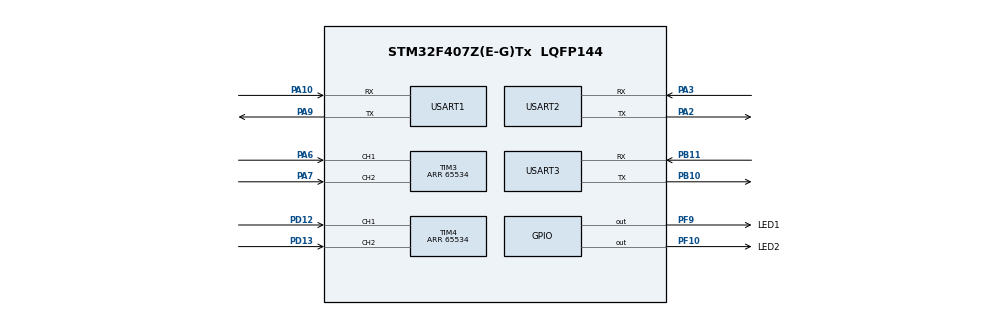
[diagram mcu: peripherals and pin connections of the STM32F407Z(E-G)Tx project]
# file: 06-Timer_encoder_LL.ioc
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Dma.Request0=USART1_TX
Dma.Request1=USART2_TX
Dma.Request2=USART3_TX
Dma.USART1_TX.0.Direction=DMA_MEMORY_TO_PERIPH
Dma.USART1_TX.0.FIFOMode=DMA_FIFOMODE_DISABLE
Dma.USART1_TX.0.Instance=DMA2_Stream7
Dma.USART1_TX.0.MemDataAlignment=DMA_MDATAALIGN_BYTE
Dma.USART1_TX.0.MemInc=DMA_MINC_ENABLE
Dma.USART1_TX.0.Mode=DMA_NORMAL
Dma.USART1_TX.0.PeriphDataAlignment=DMA_PDATAALIGN_BYTE
Dma.USART1_TX.0.PeriphInc=DMA_PINC_DISABLE
Dma.USART1_TX.0.Priority=DMA_PRIORITY_LOW
Dma.USART2_TX.1.Direction=DMA_MEMORY_TO_PERIPH
Dma.USART2_TX.1.FIFOMode=DMA_FIFOMODE_DISABLE
Dma.USART2_TX.1.Instance=DMA1_Stream6
Dma.USART2_TX.1.MemDataAlignment=DMA_MDATAALIGN_BYTE
Dma.USART2_TX.1.MemInc=DMA_MINC_ENABLE
Dma.USART2_TX.1.Mode=DMA_NORMAL
Dma.USART2_TX.1.PeriphDataAlignment=DMA_PDATAALIGN_BYTE
Dma.USART2_TX.1.PeriphInc=DMA_PINC_DISABLE
Dma.USART2_TX.1.Priority=DMA_PRIORITY_LOW
Dma.USART3_TX.2.Direction=DMA_MEMORY_TO_PERIPH
Dma.USART3_TX.2.FIFOMode=DMA_FIFOMODE_DISABLE
Dma.USART3_TX.2.Instance=DMA1_Stream3
Dma.USART3_TX.2.MemDataAlignment=DMA_MDATAALIGN_BYTE
Dma.USART3_TX.2.MemInc=DMA_MINC_ENABLE
Dma.USART3_TX.2.Mode=DMA_NORMAL
Dma.USART3_TX.2.PeriphDataAlignment=DMA_PDATAALIGN_BYTE
Dma.USART3_TX.2.PeriphInc=DMA_PINC_DISABLE
Dma.USART3_TX.2.Priority=DMA_PRIORITY_LOW
Mcu.Family=STM32F4
Mcu.Name=STM32F407Z(E-G)Tx
Mcu.Package=LQFP144
NVIC.DMA1_Stream3_IRQn=true\:0\:0\:false\:false\:true\:false\:true
NVIC.DMA1_Stream6_IRQn=true\:0\:0\:false\:false\:true\:false\:true
NVIC.DMA2_Stream7_IRQn=true\:0\:0\:false\:false\:true\:false\:true
NVIC.PriorityGroup=NVIC_PRIORITYGROUP_4
NVIC.TIM2_IRQn=true\:0\:0\:false\:false\:true\:true\:true
PA10.Mode=Asynchronous
PA10.Signal=USART1_RX
PA13.Mode=Serial_Wire
PA13.Signal=SYS_JTMS-SWDIO
PA14.Mode=Serial_Wire
PA14.Signal=SYS_JTCK-SWCLK
PA2.Mode=Asynchronous
PA2.Signal=USART2_TX
PA3.Mode=Asynchronous
PA3.Signal=USART2_RX
PA6.Signal=S_TIM3_CH1
PA7.Signal=S_TIM3_CH2
PA9.Mode=Asynchronous
PA9.Signal=USART1_TX
PB10.Mode=Asynchronous
PB10.Signal=USART3_TX
PB11.Mode=Asynchronous
PB11.Signal=USART3_RX
PD12.Signal=S_TIM4_CH1
PD13.Signal=S_TIM4_CH2
PF10.GPIO_Label=LED2
PF10.PinState=GPIO_PIN_SET
PF10.Signal=GPIO_Output
PF9.GPIO_Label=LED1
PF9.PinState=GPIO_PIN_SET
PF9.Signal=GPIO_Output
PH0-OSC_IN.Mode=HSE-External-Oscillator
PH0-OSC_IN.Signal=RCC_OSC_IN
PH1-OSC_OUT.Mode=HSE-External-Oscillator
PH1-OSC_OUT.Signal=RCC_OSC_OUT
ProjectManager.HeapSize=0x200
ProjectManager.StackSize=0x400
ProjectManager.TargetToolchain=MDK-ARM V5
RCC.48MHZClocksFreq_Value=84000000
RCC.AHBFreq_Value=168000000
RCC.APB1CLKDivider=RCC_HCLK_DIV4
RCC.APB1Freq_Value=42000000
RCC.APB1TimFreq_Value=84000000
RCC.APB2CLKDivider=RCC_HCLK_DIV2
RCC.APB2Freq_Value=84000000
RCC.APB2TimFreq_Value=168000000
RCC.CortexFreq_Value=168000000
RCC.HCLKFreq_Value=168000000
RCC.HSE_VALUE=8000000
RCC.HSI_VALUE=16000000
RCC.LSE_VALUE=32768
RCC.PLLM=8
RCC.PLLN=168
RCC.SYSCLKFreq_VALUE=168000000
RCC.SYSCLKSource=RCC_SYSCLKSOURCE_PLLCLK
RCC.VCOOutputFreq_Value=336000000
SH.S_TIM3_CH1.0=TIM3_CH1,Encoder_Interface
SH.S_TIM3_CH2.0=TIM3_CH2,Encoder_Interface
SH.S_TIM4_CH1.0=TIM4_CH1,Encoder_Interface
SH.S_TIM4_CH2.0=TIM4_CH2,Encoder_Interface
TIM2.Period=999
TIM2.Prescaler=8399
TIM3.EncoderMode=TIM_ENCODERMODE_TI12
TIM3.Period=65534
TIM4.EncoderMode=TIM_ENCODERMODE_TI12
TIM4.Period=65534
USART1.VirtualMode=VM_ASYNC
USART2.VirtualMode=VM_ASYNC
USART3.VirtualMode=VM_ASYNC
VP_TIM2_VS_ClockSourceINT.Mode=Internal
board=custom

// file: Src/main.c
/* USER CODE BEGIN Header */
/**
  ******************************************************************************
  * @file           : main.c
  * @brief          : Main program body
  ******************************************************************************
  * @attention
  *
  * <h2><center>&copy; Copyright (c) 2019 STMicroelectronics.
  * All rights reserved.</center></h2>
  *
  * This software component is licensed by ST under BSD 3-Clause license,
  * the "License"; You may not use this file except in compliance with the
  * License. You may obtain a copy of the License at:
  *                        opensource.org/licenses/BSD-3-Clause
  *
  ******************************************************************************
  */
/* USER CODE END Header */

#include "main.h"
#include "dma.h"
#include "tim.h"
#include "usart.h"
#include "gpio.h"

void SystemClock_Config(void);
/* USER CODE BEGIN PFP */

void user_init(void);

/* USER CODE END PFP */

int main(void)
{

  /* MCU Configuration--------------------------------------------------------*/

  /* Reset of all peripherals, Initializes the Flash interface and the Systick. */

  LL_APB2_GRP1_EnableClock(LL_APB2_GRP1_PERIPH_SYSCFG);
  LL_APB1_GRP1_EnableClock(LL_APB1_GRP1_PERIPH_PWR);

  NVIC_SetPriorityGrouping(NVIC_PRIORITYGROUP_4);

  /* System interrupt init*/

  /* Configure the system clock */
  SystemClock_Config();

  /* Initialize all configured peripherals */
  MX_GPIO_Init();
  MX_DMA_Init();
  MX_TIM2_Init();
  MX_TIM3_Init();
  MX_TIM4_Init();
  MX_USART1_UART_Init();
  MX_USART2_UART_Init();
  MX_USART3_UART_Init();
  /* USER CODE BEGIN 2 */

  user_init();

  /* USER CODE END 2 */

  /* Infinite loop */
  while (1)
  {

  }
}

void SystemClock_Config(void)
{
  LL_FLASH_SetLatency(LL_FLASH_LATENCY_5);

  if(LL_FLASH_GetLatency() != LL_FLASH_LATENCY_5)
  {
  Error_Handler();
  }
  LL_PWR_SetRegulVoltageScaling(LL_PWR_REGU_VOLTAGE_SCALE1);
  LL_RCC_HSI_SetCalibTrimming(16);
  LL_RCC_HSI_Enable();

   /* Wait till HSI is ready */
  while(LL_RCC_HSI_IsReady() != 1)
  {

  }
  LL_RCC_PLL_ConfigDomain_SYS(LL_RCC_PLLSOURCE_HSI, LL_RCC_PLLM_DIV_8, 168, LL_RCC_PLLP_DIV_2);
  LL_RCC_PLL_Enable();

   /* Wait till PLL is ready */
  while(LL_RCC_PLL_IsReady() != 1)
  {

  }
  LL_RCC_SetAHBPrescaler(LL_RCC_SYSCLK_DIV_1);
  LL_RCC_SetAPB1Prescaler(LL_RCC_APB1_DIV_4);
  LL_RCC_SetAPB2Prescaler(LL_RCC_APB2_DIV_2);
  LL_RCC_SetSysClkSource(LL_RCC_SYS_CLKSOURCE_PLL);

   /* Wait till System clock is ready */
  while(LL_RCC_GetSysClkSource() != LL_RCC_SYS_CLKSOURCE_STATUS_PLL)
  {

  }
  LL_Init1msTick(168000000);
  LL_SYSTICK_SetClkSource(LL_SYSTICK_CLKSOURCE_HCLK);
  LL_SetSystemCoreClock(168000000);
}

/* USER CODE BEGIN 4 */

void user_init(void)
{
    user_usart_init();

    LL_TIM_EnableIT_UPDATE(TIM2);

    LL_TIM_EnableCounter(TIM3);
    LL_TIM_EnableCounter(TIM4);
    LL_TIM_EnableCounter(TIM2);
}

/* USER CODE END 4 */

void Error_Handler(void)
{
}

/************************ (C) COPYRIGHT STMicroelectronics *****END OF FILE****/
